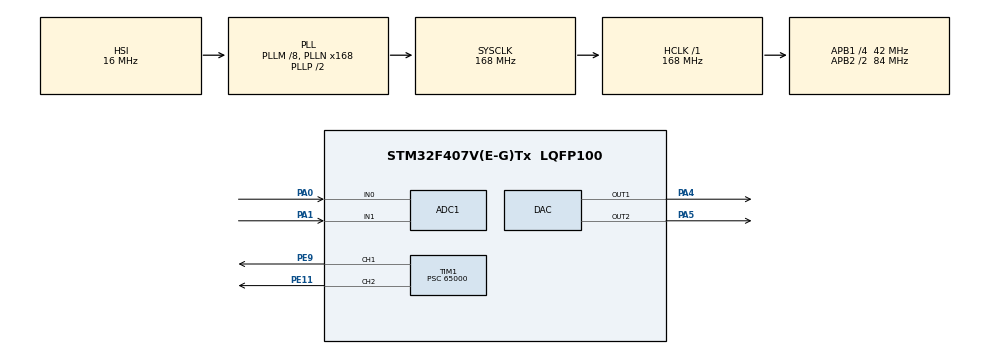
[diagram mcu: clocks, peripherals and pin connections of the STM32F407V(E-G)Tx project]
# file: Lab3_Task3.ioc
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ADC1.Channel-0\#ChannelRegularConversion=ADC_CHANNEL_0
ADC1.Channel-1\#ChannelRegularConversion=ADC_CHANNEL_1
ADC1.ContinuousConvMode=ENABLE
ADC1.DMAContinuousRequests=ENABLE
ADC1.NbrOfConversion=2
ADC1.NbrOfConversionFlag=1
ADC1.Rank-0\#ChannelRegularConversion=1
ADC1.Rank-1\#ChannelRegularConversion=2
ADC1.SamplingTime-0\#ChannelRegularConversion=ADC_SAMPLETIME_480CYCLES
ADC1.SamplingTime-1\#ChannelRegularConversion=ADC_SAMPLETIME_480CYCLES
ADC1.ScanConvMode=ENABLE
ADC1.master=1
Dma.ADC1.0.Direction=DMA_PERIPH_TO_MEMORY
Dma.ADC1.0.FIFOMode=DMA_FIFOMODE_DISABLE
Dma.ADC1.0.Instance=DMA2_Stream0
Dma.ADC1.0.MemDataAlignment=DMA_MDATAALIGN_HALFWORD
Dma.ADC1.0.MemInc=DMA_MINC_ENABLE
Dma.ADC1.0.Mode=DMA_CIRCULAR
Dma.ADC1.0.PeriphDataAlignment=DMA_PDATAALIGN_HALFWORD
Dma.ADC1.0.PeriphInc=DMA_PINC_DISABLE
Dma.ADC1.0.Priority=DMA_PRIORITY_LOW
Dma.Request0=ADC1
Mcu.Family=STM32F4
Mcu.Name=STM32F407V(E-G)Tx
Mcu.Package=LQFP100
NVIC.DMA2_Stream0_IRQn=true\:0\:0\:false\:false\:true\:false\:true\:true
NVIC.PriorityGroup=NVIC_PRIORITYGROUP_4
PA0-WKUP.Signal=ADCx_IN0
PA1.Signal=ADCx_IN1
PA13.Mode=Serial_Wire
PA13.Signal=SYS_JTMS-SWDIO
PA14.Mode=Serial_Wire
PA14.Signal=SYS_JTCK-SWCLK
PA4.Signal=COMP_DAC1_group
PA5.Signal=COMP_DAC2_group
PE11.Signal=S_TIM1_CH2
PE9.Signal=S_TIM1_CH1
PH0-OSC_IN.Mode=HSE-External-Oscillator
PH0-OSC_IN.Signal=RCC_OSC_IN
PH1-OSC_OUT.Mode=HSE-External-Oscillator
PH1-OSC_OUT.Signal=RCC_OSC_OUT
ProjectManager.HeapSize=0x200
ProjectManager.StackSize=0x400
ProjectManager.TargetToolchain=STM32CubeIDE
RCC.48MHZClocksFreq_Value=84000000
RCC.AHBFreq_Value=168000000
RCC.APB1CLKDivider=RCC_HCLK_DIV4
RCC.APB1Freq_Value=42000000
RCC.APB1TimFreq_Value=84000000
RCC.APB2CLKDivider=RCC_HCLK_DIV2
RCC.APB2Freq_Value=84000000
RCC.APB2TimFreq_Value=168000000
RCC.CortexFreq_Value=168000000
RCC.HCLKFreq_Value=168000000
RCC.HSE_VALUE=25000000
RCC.HSI_VALUE=16000000
RCC.LSE_VALUE=32768
RCC.PLLM=8
RCC.PLLN=168
RCC.SYSCLKFreq_VALUE=168000000
RCC.SYSCLKSource=RCC_SYSCLKSOURCE_PLLCLK
RCC.VCOOutputFreq_Value=336000000
SH.ADCx_IN0.0=ADC1_IN0,IN0
SH.ADCx_IN1.0=ADC1_IN1,IN1
SH.COMP_DAC1_group.0=DAC_OUT1,DAC_OUT1
SH.COMP_DAC2_group.0=DAC_OUT2,DAC_OUT2
SH.S_TIM1_CH1.0=TIM1_CH1,PWM Generation1 CH1
SH.S_TIM1_CH2.0=TIM1_CH2,PWM Generation2 CH2
TIM1.Channel-PWM\ Generation1\ CH1=TIM_CHANNEL_1
TIM1.Channel-PWM\ Generation2\ CH2=TIM_CHANNEL_2
TIM1.Period=100
TIM1.Prescaler=65000
TIM1.Pulse-PWM\ Generation1\ CH1=20
TIM1.Pulse-PWM\ Generation2\ CH2=80
VP_TIM1_VS_ClockSourceINT.Mode=Internal
board=custom

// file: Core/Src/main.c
/* USER CODE BEGIN Header */
/**
  ******************************************************************************
  * @file           : main.c
  * @brief          : Main program body
  ******************************************************************************
  * @attention
  *
  * Copyright (c) 2023 STMicroelectronics.
  * All rights reserved.
  *
  * This software is licensed under terms that can be found in the LICENSE file
  * in the root directory of this software component.
  * If no LICENSE file comes with this software, it is provided AS-IS.
  *
  ******************************************************************************
  */
/* USER CODE END Header */
#include "main.h"
#include "adc.h"
#include "dac.h"
#include "dma.h"
#include "tim.h"
#include "gpio.h"

void SystemClock_Config(void);

int main(void)
{
  /* USER CODE BEGIN 1 */
  uint16_t buf[2];
  /* USER CODE END 1 */

  /* MCU Configuration--------------------------------------------------------*/

  /* Reset of all peripherals, Initializes the Flash interface and the Systick. */
  HAL_Init();

  /* Configure the system clock */
  SystemClock_Config();

  /* Initialize all configured peripherals */
  MX_GPIO_Init();
  MX_DMA_Init();
  MX_ADC1_Init();
  MX_DAC_Init();
  MX_TIM1_Init();
  /* USER CODE BEGIN 2 */
  HAL_TIM_PWM_Start(&htim1, TIM_CHANNEL_1);
  HAL_TIM_PWM_Start(&htim1, TIM_CHANNEL_2);

  HAL_DAC_Start(&hdac, DAC_CHANNEL_1);
  HAL_DAC_Start(&hdac, DAC_CHANNEL_2);

  HAL_ADC_Start_DMA(&hadc1, (uint32_t*) buf, 2);
  /* USER CODE END 2 */

  /* Infinite loop */
  /* USER CODE BEGIN WHILE */
  while (1)
  {
	HAL_DAC_SetValue(&hdac, DAC_CHANNEL_1, DAC_ALIGN_12B_R, buf[0]);
	HAL_DAC_SetValue(&hdac, DAC_CHANNEL_2, DAC_ALIGN_12B_R, buf[1]);
    /* USER CODE END WHILE */

  }
}

void SystemClock_Config(void)
{
  RCC_OscInitTypeDef RCC_OscInitStruct = {0};
  RCC_ClkInitTypeDef RCC_ClkInitStruct = {0};

  /** Configure the main internal regulator output voltage
  */
  __HAL_RCC_PWR_CLK_ENABLE();
  __HAL_PWR_VOLTAGESCALING_CONFIG(PWR_REGULATOR_VOLTAGE_SCALE1);

  /** Initializes the RCC Oscillators according to the specified parameters
  * in the RCC_OscInitTypeDef structure.
  */
  RCC_OscInitStruct.OscillatorType = RCC_OSCILLATORTYPE_HSI;
  RCC_OscInitStruct.HSIState = RCC_HSI_ON;
  RCC_OscInitStruct.HSICalibrationValue = RCC_HSICALIBRATION_DEFAULT;
  RCC_OscInitStruct.PLL.PLLState = RCC_PLL_ON;
  RCC_OscInitStruct.PLL.PLLSource = RCC_PLLSOURCE_HSI;
  RCC_OscInitStruct.PLL.PLLM = 8;
  RCC_OscInitStruct.PLL.PLLN = 168;
  RCC_OscInitStruct.PLL.PLLP = RCC_PLLP_DIV2;
  RCC_OscInitStruct.PLL.PLLQ = 4;
  if (HAL_RCC_OscConfig(&RCC_OscInitStruct) != HAL_OK)
  {
    Error_Handler();
  }

  /** Initializes the CPU, AHB and APB buses clocks
  */
  RCC_ClkInitStruct.ClockType = RCC_CLOCKTYPE_HCLK|RCC_CLOCKTYPE_SYSCLK
                              |RCC_CLOCKTYPE_PCLK1|RCC_CLOCKTYPE_PCLK2;
  RCC_ClkInitStruct.SYSCLKSource = RCC_SYSCLKSOURCE_PLLCLK;
  RCC_ClkInitStruct.AHBCLKDivider = RCC_SYSCLK_DIV1;
  RCC_ClkInitStruct.APB1CLKDivider = RCC_HCLK_DIV4;
  RCC_ClkInitStruct.APB2CLKDivider = RCC_HCLK_DIV2;

  if (HAL_RCC_ClockConfig(&RCC_ClkInitStruct, FLASH_LATENCY_5) != HAL_OK)
  {
    Error_Handler();
  }
}

void Error_Handler(void)
{
  __disable_irq();
  while (1)
  {
  }
}
